# M55M1 register map
File version: 1.0
Registers are 32-bit, read-write, reset 0x0 unless marked. A register's access mark holds for its fields unless they carry their own. Offsets are from the block's base; [hi:lo] are bit positions; {n}, {i} and the like mark numbered series; 'fields as' and 'values as' point back to an identical list.

## EADC_NS — EADC Register Map
Base 0x50241000
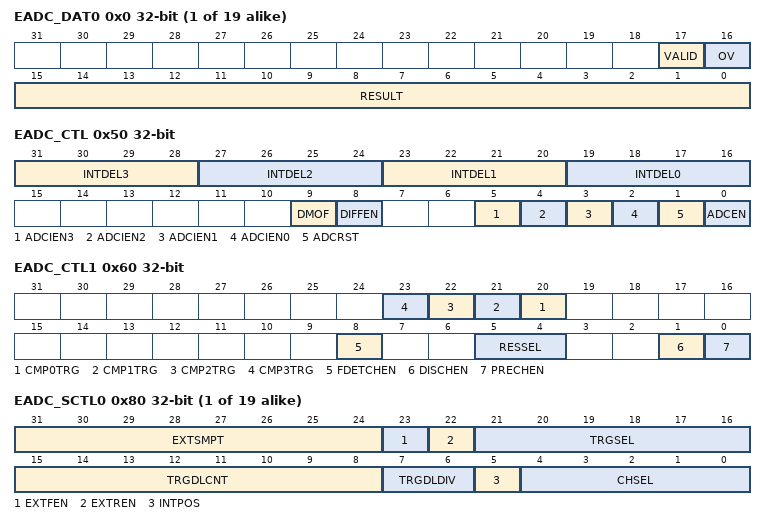
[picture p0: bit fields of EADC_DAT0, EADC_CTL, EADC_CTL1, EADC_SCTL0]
{0x0+4i} EADC_DAT{i} ro (i=0..18) — EADC Data Register {i} for Sample Module {i}
  [17] VALID — Valid Flag. This bit is set to 1 when corresponding sample module channel analog input conversion is completed and cleared by hardware after EADC_DAT register is read.
    0=Data in RESULT[11:0] bits is not valid; 1=Data in RESULT[11:0] bits is valid
  [16] OV — Overrun Flag. If converted data in RESULT[11:0] has not been read before new conversion result is loaded to this register, OV is set to 1. Note: It is cleared by hardware after EADC_DAT register is read.
    0=Data in RESULT[11:0] is recent conversion result; 1=Data in RESULT[11:0] is overwrite
  [15:0] RESULT — EADC Conversion Result. This field contains 12 bits conversion result. The 12-bit EADC conversion result with unsigned format will be filled in RESULT[11:0] and zero will be filled in RESULT[15:12]. Note: When operating in oversampling mode, RESULT[15:0] can represent oversampling results.
0x4C EADC_CURDAT ro — EADC PDMA Current Transfer Data Register
  [27:0] CURDAT — EADC PDMA Current Transfer Data. Note: these bits are read only
0x50 EADC_CTL — EADC Control Register
  [31:28] INTDEL3 — ADC Start Of Conversion ADINT3 Delay Cycle Selection. Start of conversion interrupt ADINT3 will delay INTDEL3 PCLK cycles to generate interrupt. The function support delay 1 PCLK to 15 PCLK cycles, user can select one of the options according to the relationship of PCLK and ADC _CLK which user selected. Note: It is noted that the delayed interrupt ADINT3 must occurs before the next ADINT3 generated when use the same sample module to control EADC conversion.
  [27:24] INTDEL2 — ADC Start Of Conversion ADINT2 Delay Cycle Selection. Start of conversion interrupt ADINT2 will delay INTDEL2 PCLK cycles to generate interrupt. The function support delay 1 PCLK to 15 PCLK cycles, user can select one of the options according to the relationship of PCLK and ADC _CLK which user which user selected. Note: It is noted that the delayed interrupt ADINT2 must occurs before the next ADINT2 generated when use the same sample module to control EADC conversion.
  [23:20] INTDEL1 — ADC Start Of Conversion ADINT1 Delay Cycle Selection. Start of conversion interrupt ADINT1 will delay INTDEL1 PCLK cycles to generate interrupt. The function support delay 1 PCLK to 15 PCLK cycles, user can select one of the options according to the relationship of PCLK and ADC _CLK which user selected. Note: It is noted that the delayed interrupt ADINT1 must occurs before the next ADINT1 generated when use the same sample module to control EADC conversion.
  [19:16] INTDEL0 — ADC Start Of Conversion ADINT0 Delay Cycle Selection. Start of conversion interrupt ADINT0 will delay INTDEL0 PCLK cycles to generate interrupt. The function support delay 1 PCLK to 15 PCLK cycles, user can select one of the options according to the relationship of PCLK and ADC _CLK which user selected. Note: It is noted that the delayed interrupt ADINT0 must occurs before the next ADINT0 generated when use the same sample module to control EADC conversion.
  [9] DMOF — ADC Differential Input Mode Output Format
    0=ADC conversion result will be filled in RESULT (EADC_DATn[15:0], where n= 0 ~27) with unsigned format; 1=ADC conversion result will be filled in RESULT (EADC_DATn[15:0], where n= 0 ~27) with 2'complement format
  [8] DIFFEN — Differential Analog Input Mode Enable Bit
    0=Single-end analog input mode; 1=Differential analog input mode
  [5] ADCIEN3 — Specific Sample Module EADC ADINT3 Interrupt Enable Bit. The EADC converter generates a conversion end ADIF3 (EADC_STATUS2[3]) upon the end of specific sample module EADC conversion. If EADCIEN3 bit is set then conversion end interrupt request ADINT3 is generated.
    0=Specific sample module EADC ADINT3 interrupt function Disabled; 1=Specific sample module EADC ADINT3 interrupt function Enabled
  [4] ADCIEN2 — Specific Sample Module EADC ADINT2 Interrupt Enable Bit. The EADC converter generates a conversion end ADIF2 (EADC_STATUS2[2]) upon the end of specific sample module EADC conversion. If EADCIEN2 bit is set then conversion end interrupt request ADINT2 is generated.
    0=Specific sample module EADC ADINT2 interrupt function Disabled; 1=Specific sample module EADC ADINT2 interrupt function Enabled
  [3] ADCIEN1 — Specific Sample Module EADC ADINT1 Interrupt Enable Bit. The EADC converter generates a conversion end ADIF1 (EADC_STATUS2[1]) upon the end of specific sample module EADC conversion. If EADCIEN1 bit is set then conversion end interrupt request ADINT1 is generated.
    0=Specific sample module EADC ADINT1 interrupt function Disabled; 1=Specific sample module EADC ADINT1 interrupt function Enabled
  [2] ADCIEN0 — Specific Sample Module EADC ADINT0 Interrupt Enable Bit. The EADC converter generates a conversion end ADIF0 (EADC_STATUS2[0]) upon the end of specific sample module EADC conversion. If ADCIEN0 bit is set then conversion end interrupt request ADINT0 is generated.
    0=Specific sample module EADC ADINT0 interrupt function Disabled; 1=Specific sample module EADC ADINT0 interrupt function Enabled
  [1] ADCRST — EADC Converter Control Circuits Reset. Note: ADCRST bit remains 1 during EADC reset, when EADC reset end, the ADCRST bit is automatically cleared to 0.
    0=No effect; 1=Cause EADC control circuits reset to initial state, but not change the EADC registers value
  [0] ADCEN — EADC Converter Enable Bit. Note: Before starting EADC conversion function, this bit should be set to 1. Clear it to 0 to disable EADC converter analog circuit power consumption.
    0=EADC Disabled; 1=EADC Enabled
0x54 EADC_SWTRG wo — EADC Sample Module Software Start Register
  [27:0] SWTRG — EADC Sample Module 0~27 Software Force to Start EADC Conversion. Note: After writing this register to start EADC conversion, the EADC_PENDSTS register will show which sample module will conversion. If user want to disable the conversion of the sample module, user can write EADC_PENDSTS register to clear it.
    0=No effect; 1=Cause an EADC conversion when the priority is given to sample module
0x58 EADC_PENDSTS — EADC Start of Conversion Pending Flag Register
  [27:0] STPF — EADC Sample Module 0~27 Start of Conversion Pending Flag. Read Operation:
    0=There is no pending conversion for sample module; 1=Sample module EADC start of conversion is pending. Clear pending flag cancel the conversion for sample module
0x5C EADC_OVSTS — EADC Sample Module Start of Conversion Overrun Flag Register
  [27:0] SPOVF — EADC SAMPLE0~27 Overrun Flag. Note: This bit is cleared by writing 1 to it.
    0=No sample module event overrun; 1=Indicates a new sample module event is generated while an old one event is pending
0x60 EADC_CTL1 — EADC Control1 Register
  [n+20] CMP{n}TRG (n=0..3) — ADC Comparator {n} Trigger EPWM Brake Enable Bit
    0=Comparator {n} trigger EPWM brake is disabled; 1=Comparator {n} trigger EPWM brake is enabled
  [8] FDETCHEN — Floating Detect Channel Enable Bit
    0=Floating Detect Channel Disabled; 1=Floating Detect Channel Enabled
  [5:4] RESSEL — Resolution Select Bits
    0=ADC resolution 12 bits; 1=ADC resolution 10 bits; 2=ADC resolution 8 bits
  [1] DISCHEN — Discharge Enable Bit. Note: Analog input voltage is 1/2 VREF when PRECHEN and DISCHEN are all enable.
    0=Channel discharge Disabled; 1=Channel discharge Enabled
  [0] PRECHEN — Precharge Enable Bit. Note: Analog input voltage is 1/2 VREF when PRECHEN and DISCHEN are all enable.
    0=Channel precharge Disabled; 1=Channel precharge Enabled
{0x80+4i} EADC_SCTL{i} (i=0..18) — EADC Sample Module {i} Control Register
  [31:24] EXTSMPT — EADC Sampling Time Extend. When EADC converting at high conversion rate, the sampling time of analog input voltage may not be enough if input channel loading is heavy, and software can extend EADC sampling time after trigger source is coming to get enough sampling time.
  [23] EXTFEN — EADC External Trigger Falling Edge Enable Bit
    0=Falling edge Disabled when EADC selects EADC_ST as trigger source; 1=Falling edge Enabled when EADC selects EADC_ST as trigger source
  [22] EXTREN — EADC External Trigger Rising Edge Enable Bit
    0=Rising edge Disabled when EADC selects EADC_ST as trigger source; 1=Rising edge Enabled when EADC selects EADC_ST as trigger source
  [21:16] TRGSEL — EADC Sample Module Start of Conversion Trigger Source Selection
  [15:8] TRGDLCNT — EADC Sample Module Start of Conversion Trigger Delay Time
  [7:6] TRGDLDIV — EADC Sample Module Start of Conversion Trigger Delay Clock Divider Selection. Trigger delay clock frequency:
    0=EADC_CLK/1; 1=EADC_CLK/2; 2=EADC_CLK/4; 3=EADC_CLK/16
  [5] INTPOS — Interrupt Flag Position Select
    0=Set ADIFn (EADC_STATUS2[n], n=0~3) at EADC end of conversion; 1=Set ADIFn (EADC_STATUS2[n], n=0~3) at EADC start of conversion
  [4:0] CHSEL — EADC Sample Module Channel Selection
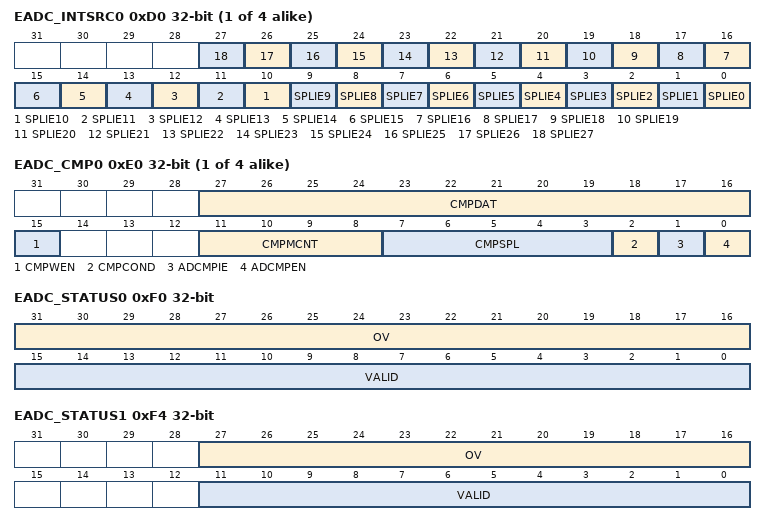
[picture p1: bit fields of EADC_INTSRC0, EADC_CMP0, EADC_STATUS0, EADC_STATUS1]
{0xD0+4i} EADC_INTSRC{i} (i=0..3) — EADC Interrupt {i} Source Enable Control Register.
  [n] SPLIE{n} (n=0..27) — Sample Module {n} Interrupt Enable Bit
    0=Sample Module {n} interrupt Disabled; 1=Sample Module {n} interrupt Enabled
{0xE0+4i} EADC_CMP{i} (i=0..3) — EADC Result Compare Register {i}
  [27:16] CMPDAT — Comparison Data. The 12 bits data is used to compare with conversion result of specified sample module. User can use it to monitor the external analog input pin voltage transition without imposing a load on software.
  [15] CMPWEN — Compare Window Mode Enable Bit. Note: This bit is only present in EADC_CMP0 and EADC_CMP2 register. Note: When in compare window mode, the CMPCNT setting only follow EADC_CMP0, EADC_CMP2 registers
    0=ADCMPF0 (EADC_STATUS2[4]) will be set when EADC_CMP0 compared condition matched. ADCMPF2 (EADC_STATUS2[6]) will be set when EADC_CMP2 compared condition matched; 1=ADCMPF0 (EADC_STATUS2[4]) will be set when both EADC_CMP0 and EADC_CMP1 compared condition matched. ADCMPF2 (EADC_STATUS2[6]) will be set when both EADC_CMP2 and EADC_CMP3 compared condition matched
  [11:8] CMPMCNT — Compare Match Count
  [7:3] CMPSPL — Compare Sample Module Selection
    {v}=Sample Module {v} conversion result EADC_DAT{v} is selected to be compared (v=0..27)
  [2] CMPCOND — Compare Condition
    0=Set the compare condition as that when a 12-bit EADC conversion result is less than the 12-bit CMPDAT (EADC_CMPn [27:16]), the internal match counter will increase one; 1=Set the compare condition as that when a 12-bit EADC conversion result is greater or equal to the 12-bit CMPDAT (EADC_CMPn [27:16]), the internal match counter will increase one
  [1] ADCMPIE — EADC Result Compare Interrupt Enable Bit
    0=Compare function interrupt Disabled; 1=Compare function interrupt Enabled
  [0] ADCMPEN — EADC Result Compare Enable Bit
    0=Compare Disabled; 1=Compare Enabled
0xF0 EADC_STATUS0 ro — EADC Status Register 0
  [31:16] OV — EADC_DAT0~15 Overrun Flag
  [15:0] VALID — EADC_DAT0~15 Data Valid Flag
0xF4 EADC_STATUS1 ro — EADC Status Register 1
  [27:16] OV — EADC_DAT16~27 Overrun Flag
  [11:0] VALID — EADC_DAT16~27 Data Valid Flag
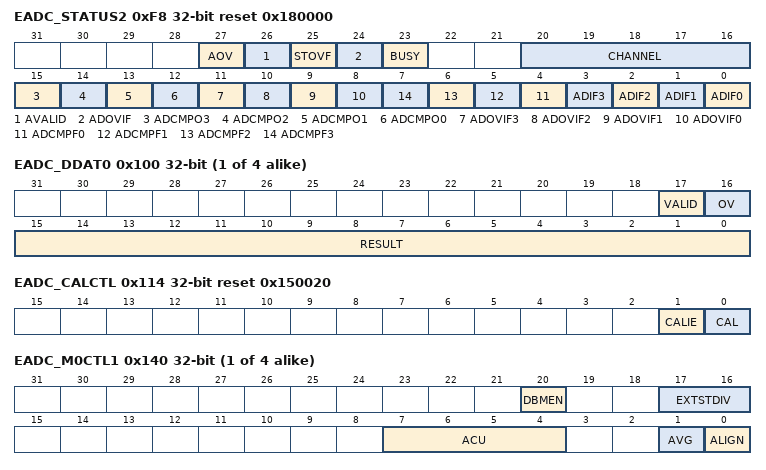
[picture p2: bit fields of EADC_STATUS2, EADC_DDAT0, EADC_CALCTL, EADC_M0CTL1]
0xF8 EADC_STATUS2 reset 0x180000 — EADC Status Register 2
  [27] AOV ro — for All Sample Module EADC Result Data Register Overrun Flags Check (Read Only). Note: This bit will keep 1 when any OVn Flag is equal to 1.
    0=None of sample module data register overrun flag OV (EADC_DATn[16]) is set to 1; 1=Any one of sample module data register overrun flag OV (EADC_DATn[16]) is set to 1
  [26] AVALID ro — for All Sample Module EADC Result Data Register EADC_DAT Data Valid Flag Check (Read Only). Note: This bit will keep 1 when any VALIDn Flag is equal to 1.
    0=None of sample module data register valid flag VALID (EADC_DATn[17]) is set to 1; 1=Any one of sample module data register valid flag VALID (EADC_DATn[17]) is set to 1
  [25] STOVF ro — for All EADC Sample Module Start of Conversion Overrun Flags Check (Read Only). Note: This bit will keep 1 when any SPOVFn Flag is equal to 1.
    0=None of sample module event overrun flag SPOVF (EADC_OVSTS[n]) is set to 1; 1=Any one of sample module event overrun flag SPOVF (EADC_OVSTS[n]) is set to 1
  [24] ADOVIF ro — All EADC Interrupt Flag Overrun Bits Check (Read Only). Note: This bit will keep 1 when any ADOVIFn Flag is equal to 1.
    0=None of ADINT interrupt flag ADOVIFn, n=0~3 is overwritten to 1; 1=Any one of ADINT interrupt flag ADOVIFn, n=0~3 is overwritten to 1
  [23] BUSY ro — Busy/Idle (Read Only). Note: this flag will be high after 4*EADC_CLK cycles, when the trigger source is coming.
    0=EADC is in idle state; 1=EADC is busy at conversion
  [20:16] CHANNEL ro — Current Conversion Channel (Read Only)
  [15] ADCMPO3 ro — EADC Compare 3 Output Status (Read Only). The 12 bits compare3 data CMPDAT (EADC_CMP3[27:16]) is used to compare with conversion result of specified sample module. User can use it to monitor the external analog input pin voltage status.
    0=Conversion result in EADC_DAT less than CMPDAT3 setting; 1=Conversion result in EADC_DAT greater than or equal to CMPDAT3 setting
  [14] ADCMPO2 ro — EADC Compare 2 Output Status (Read Only). The 12 bits compare2 data CMPDAT (EADC_CMP2[27:16]) is used to compare with conversion result of specified sample module. User can use it to monitor the external analog input pin voltage status.
    0=Conversion result in EADC_DAT less than CMPDAT2 setting; 1=Conversion result in EADC_DAT greater than or equal to CMPDAT2 setting
  [13] ADCMPO1 ro — EADC Compare 1 Output Status (Read Only). The 12 bits compare1 data CMPDAT (EADC_CMP1[27:16]) is used to compare with conversion result of specified sample module. User can use it to monitor the external analog input pin voltage status.
    0=Conversion result in EADC_DAT less than CMPDAT1 setting; 1=Conversion result in EADC_DAT greater than or equal to CMPDAT1 setting
  [12] ADCMPO0 ro — EADC Compare 0 Output Status (Read Only). The 12 bits compare0 data CMPDAT (EADC_CMP0[27:16]) is used to compare with conversion result of specified sample module. User can use it to monitor the external analog input pin voltage status.
    0=Conversion result in EADC_DAT less than CMPDAT0 setting; 1=Conversion result in EADC_DAT greater than or equal CMPDAT0 setting
  [11] ADOVIF3 — EADC ADINT3 Interrupt Flag Overrun. Note: This bit is cleared by writing 1 to it.
    0=ADINT3 interrupt flag is not overwritten to 1; 1=ADINT3 interrupt flag is overwritten to 1
  [10] ADOVIF2 — EADC ADINT2 Interrupt Flag Overrun. Note: This bit is cleared by writing 1 to it.
    0=ADINT2 interrupt flag is not overwritten to 1; 1=ADINT2 interrupt flag is s overwritten to 1
  [9] ADOVIF1 — EADC ADINT1 Interrupt Flag Overrun. Note: This bit is cleared by writing 1 to it.
    0=ADINT1 interrupt flag is not overwritten to 1; 1=ADINT1 interrupt flag is overwritten to 1
  [8] ADOVIF0 — EADC ADINT0 Interrupt Flag Overrun. Note: This bit is cleared by writing 1 to it.
    0=ADINT0 interrupt flag is not overwritten to 1; 1=ADINT0 interrupt flag is overwritten to 1
  [n+4] ADCMPF{n} (n=0..3) — EADC Compare {n} Flag. When the specific sample module EADC conversion result meets setting condition in EADC_CMP{n} then this bit is set to 1. Note: This bit is cleared by writing 1 to it.
    0=Conversion result in EADC_DAT does not meet EADC_CMP{n} register setting; 1=Conversion result in EADC_DAT meets EADC_CMP{n} register setting
  [n] ADIF{n} (n=0..3) — EADC ADINT{n} Interrupt Flag. Note 1: This bit is cleared by writing 1 to it. Note 2:This bit indicates whether an EADC conversion of specific sample module has been completed
    0=No ADINT{n} interrupt pulse received; 1=ADINT{n} interrupt pulse has been received
0xFC EADC_STATUS3 ro reset 0x3F — EADC Status Register 3
  [5:0] CURSPL — EADC Current Sample Module (Read Only). This register shows the current EADC is controlled by which sample module control logic modules. If the EADC is Idle, the bit filed will set to 0x3F.
{0x100+4i} EADC_DDAT{i} ro (i=0..3) — EADC Double Data Register {i} for Sample Module {i}
  [17] VALID — Valid Flag
    0=Double data in RESULT (EADC_DDATn[11:0]) is not valid; 1=Double data in RESULT (EADC_DDATn[11:0]) is valid
  [16] OV — Overrun Flag. If converted data in RESULT[15:0] has not been read before new conversion result is loaded to this register, OV is set to 1. It is cleared by hardware after EADC_DDAT register is read.
    0=Double Data in RESULT (EADC_DDATn[11:0], n=0~3) is recent conversion result; 1=Double Data in RESULT (EADC_DDATn[11:0], n=0~3) is overwrite
  [15:0] RESULT — EADC Conversion Results. This field contains 12 bits conversion results. The 12-bit EADC conversion result with unsigned format will be filled in RESULT [11:0] and zero will be filled in RESULT [15:12].
0x114 EADC_CALCTL reset 0x150020 — EADC Calibration Control Register
  [1] CALIE — Calibration Interrupt Enable Bit
    0=Calibration interrupt Disabled; 1=Calibration interrupt Enabled
  [0] CAL — Calibration Enable Bit. Note: This bit is hardware auto cleared when calibration is done
    0=Calibration Disabled; 1=Calibration Enabled
0x118 EADC_CALSR — EADC Calibration Status Register
  [16] CALIF — Calibration Finish Interrupt Flag. If calibration is finished, this flag will be set to 1. It is cleared by writing 1 to it.
0x130 EADC_PDMACTL — EADC PDMA Control Register
  [27:0] PDMATEN — PDMA Transfer Enable Bit. When EADC conversion is completed, the converted data is loaded into EADC_DATn (n: 0 ~ 27) register, user can enable this bit to generate a PDMA data transfer request.
    0=PDMA data transfer Disabled; 1=PDMA data transfer Enabled
{0x140+4i} EADC_M{i}CTL1 (i=0..3) — EADC Sample Module {i} Control Register 1
  [20] DBMEN — Double Buffer Mode Enable Bit
    0=Sample has one sample result register (default); 1=Sample has two sample result registers
  [17:16] EXTSTDIV — EADC Extended Sampling Time Clock Divider Selection. Clock frequency for extending sampling time:
    0=EADC_CLK/1; 1=EADC_CLK/2; 2=EADC_CLK/4; 3=EADC_CLK/16
  [7:4] ACU — Number of Accumulated Conversion Results Selection
    0=1 conversion result will be accumulated; 1=2 conversion result will be accumulated; 2=4 conversion result will be accumulated; 3=8 conversion result will be accumulated; 4=16 conversion result will be accumulated; 5=32 conversion result will be accumulated; 6=64 conversion result will be accumulated; 7=128 conversion result will be accumulated; 8=256 conversion result will be accumulated
  [1] AVG — Average Mode Selection
    0=Conversion results will be stored in data register without averaging; 1=Conversion results in data register will be averaged
  [0] ALIGN — Alignment Selection
    0=The conversion result will be right aligned in data register; 1=The conversion result will be left aligned in data register
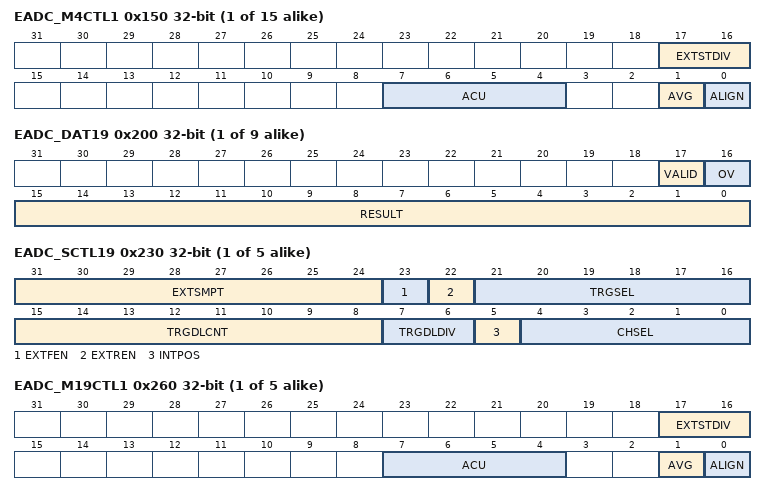
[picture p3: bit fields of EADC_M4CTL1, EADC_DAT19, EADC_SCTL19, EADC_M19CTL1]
{0x140+4i} EADC_M{i}CTL1 (i=4..18) — EADC Sample Module {i} Control Register 1
  [17:16] EXTSTDIV — EADC Extended Sampling Time Clock Divider Selection. Clock frequency for extending sampling time:
    0=EADC_CLK/1; 1=EADC_CLK/2; 2=EADC_CLK/4; 3=EADC_CLK/16
  [7:4] ACU — Number of Accumulated Conversion Results Selection
    values as EADC_M0CTL1.ACU
  [1] AVG — Average Mode Selection
    values as EADC_M0CTL1.AVG
  [0] ALIGN — Alignment Selection
    values as EADC_M0CTL1.ALIGN
{0x1B4+4i} EADC_DAT{i} ro (i=19..27) — EADC Data Register {i} for Sample Module {i}
  fields as EADC_DAT0
{0x1E4+4i} EADC_SCTL{i} (i=19..23) — EADC Sample Module {i} Control Register
  [31:24] EXTSMPT — EADC Sampling Time Extend. When EADC converting at high conversion rate, the sampling time of analog input voltage may not be enough if input channel loading is heavy, and software can extend EADC sampling time after trigger source is coming to get enough sampling time.
  [23] EXTFEN — EADC External Trigger Falling Edge Enable Bit
    0=Falling edge Disabled when EADC selects EADC_ST(x=0, 1) as trigger source; 1=Falling edge Enabled when EADC selects EADC_ST(x=0, 1) as trigger source
  [22] EXTREN — EADC External Trigger Rising Edge Enable Bit
    0=Rising edge Disabled when EADC selects EADC_ST(x=0, 1) as trigger source; 1=Rising edge Enabled when EADC selects EADC_ST(x=0, 1) as trigger source
  [21:16] TRGSEL — EADC Sample Module Start of Conversion Trigger Source Selection
  [15:8] TRGDLCNT — EADC Sample Module Start of Conversion Trigger Delay Time
  [7:6] TRGDLDIV — EADC Sample Module Start of Conversion Trigger Delay Clock Divider Selection. Trigger delay clock frequency:
    0=EADC_CLK/1; 1=EADC_CLK/2; 2=EADC_CLK/4; 3=EADC_CLK/16
  [5] INTPOS — Interrupt Flag Position Select
    values as EADC_SCTL0.INTPOS
  [4:0] CHSEL — EADC Sample Module Channel Selection
{0x1E4+4i} EADC_SCTL{i} (i=24..27) — EADC Sample Module {i} Control Register
  [31:24] EXTSMPT — ADC Sampling Time Extend. When EADC converting at high conversion rate, the sampling time of analog input voltage may not be enough if input channel loading is heavy, and software can extend EADC sampling time after trigger source is coming to get enough sampling time.
{0x214+4i} EADC_M{i}CTL1 (i=19..23) — EADC Sample Module {i} Control Register 1
  fields as EADC_M4CTL1
{0x214+4i} EADC_M{i}CTL1 (i=24..27) — EADC Sample Module {i} Control Register 1
  [17:16] EXTSTDIV — EADC Extended Sampling Time Clock Divider Selection. Clock frequency for extending sampling time:
    0=EADC_CLK/1; 1=EADC_CLK/2; 2=EADC_CLK/4; 3=EADC_CLK/16
